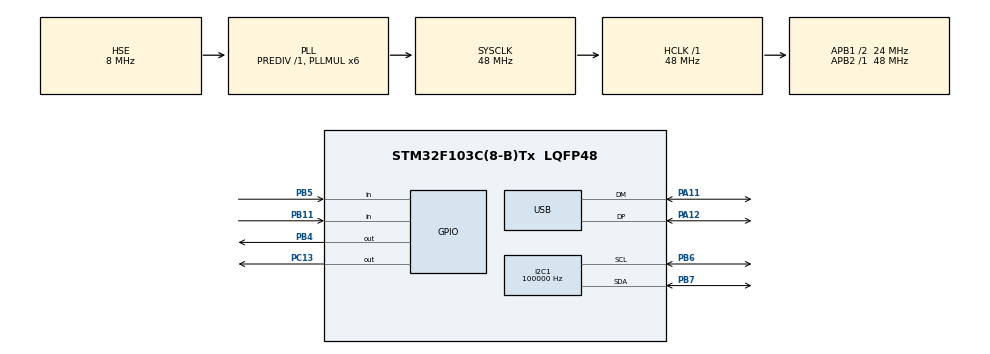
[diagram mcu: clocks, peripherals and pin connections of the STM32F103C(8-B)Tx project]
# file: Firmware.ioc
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I2C1.ClockSpeed=100000
Mcu.Family=STM32F1
Mcu.Name=STM32F103C(8-B)Tx
Mcu.Package=LQFP48
NVIC.PriorityGroup=NVIC_PRIORITYGROUP_4
NVIC.USB_LP_CAN1_RX0_IRQn=true\:0\:0\:false\:false\:true
PA11.Mode=Device
PA11.Signal=USB_DM
PA12.Mode=Device
PA12.Signal=USB_DP
PA13.Mode=Serial_Wire
PA13.Signal=SYS_JTMS-SWDIO
PA14.Mode=Serial_Wire
PA14.Signal=SYS_JTCK-SWCLK
PB11.GPIO_PuPd=GPIO_PULLUP
PB11.Signal=GPIO_Input
PB4.Signal=GPIO_Output
PB5.Signal=GPIO_Input
PB6.Mode=I2C
PB6.Signal=I2C1_SCL
PB7.Mode=I2C
PB7.Signal=I2C1_SDA
PC13-TAMPER-RTC.Signal=GPIO_Output
PD0-OSC_IN.Mode=HSE-External-Oscillator
PD0-OSC_IN.Signal=RCC_OSC_IN
PD1-OSC_OUT.Mode=HSE-External-Oscillator
PD1-OSC_OUT.Signal=RCC_OSC_OUT
ProjectManager.HeapSize=0x200
ProjectManager.StackSize=0x400
ProjectManager.TargetToolchain=MDK-ARM V5
RCC.AHBFreq_Value=48000000
RCC.APB1CLKDivider=RCC_HCLK_DIV2
RCC.APB1Freq_Value=24000000
RCC.APB1TimFreq_Value=48000000
RCC.APB2Freq_Value=48000000
RCC.APB2TimFreq_Value=48000000
RCC.HCLKFreq_Value=48000000
RCC.HSIState=RCC_HSI_ON
RCC.PLLMUL=RCC_PLL_MUL6
RCC.SYSCLKFreq_VALUE=48000000
RCC.SYSCLKSource=RCC_SYSCLKSOURCE_PLLCLK
RCC.USBFreq_Value=48000000
USB.ep0_mps=DEP0CTL_MPS_64
USB_DEVICE.CLASS_NAME_FS=CUSTOMHID
USB_DEVICE.MANUFACTURER_STRING-CUSTOM_HID_FS=A_D Electronics
USB_DEVICE.PRODUCT_STRING_CUSTOMHID_FS=Custom Touchscreen
USB_DEVICE.USBD_CUSTOMHID_OUTREPORT_BUF_SIZE-CUSTOM_HID_FS=64
USB_DEVICE.USBD_CUSTOM_HID_REPORT_DESC_SIZE-CUSTOM_HID_FS=124
USB_DEVICE.VirtualModeFS=Custom_Hid_FS
VP_USB_DEVICE_VS_USB_DEVICE_CUSTOM_HID_FS.Mode=CUSTOM_HID_FS
board=Firmware

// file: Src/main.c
#include "main.h"
#include "stm32f1xx_hal.h"
#include "usb_device.h"

/* USER CODE BEGIN Includes */
#include "GT811.h"

/* USER CODE END Includes */

I2C_HandleTypeDef hi2c1;

/* USER CODE BEGIN PV */
/* Private variables ---------------------------------------------------------*/

/* USER CODE END PV */

void SystemClock_Config(void);
void Error_Handler(void);
static void MX_GPIO_Init(void);
static void MX_I2C1_Init(void);

/* USER CODE BEGIN PFP */
/* Private function prototypes -----------------------------------------------*/

/* USER CODE END PFP */

int main(void)
{

  /* MCU Configuration----------------------------------------------------------*/

  /* Reset of all peripherals, Initializes the Flash interface and the Systick. */
  HAL_Init();

  /* Configure the system clock */
  SystemClock_Config();

  /* Initialize all configured peripherals */
  MX_GPIO_Init();
  MX_USB_DEVICE_Init();
  MX_I2C1_Init();

  /* USER CODE BEGIN 2 */

	// USB HID - https://habrahabr.ru/post/208026/
	// https://k16c.eu/2016/11/02/open-firmware-for-waveshares-7-inch-touch-screen/#more-522
	// https://github.com/pysco68/waveshare-hid

	GT811_Init();
	HAL_GPIO_WritePin(GPIOC, GPIO_PIN_13, GPIO_PIN_SET); // USB On
  /* USER CODE END 2 */

  /* Infinite loop */
  for(;;)
  {

  /* USER CODE BEGIN 3 */
		GT811_Poll();
  }
  /* USER CODE END 3 */

}

/** System Clock Configuration
*/
void SystemClock_Config(void)
{

  RCC_OscInitTypeDef RCC_OscInitStruct;
  RCC_ClkInitTypeDef RCC_ClkInitStruct;
  RCC_PeriphCLKInitTypeDef PeriphClkInit;

    /**Initializes the CPU, AHB and APB busses clocks
    */
  RCC_OscInitStruct.OscillatorType = RCC_OSCILLATORTYPE_HSE;
  RCC_OscInitStruct.HSEState = RCC_HSE_ON;
  RCC_OscInitStruct.HSEPredivValue = RCC_HSE_PREDIV_DIV1;
  RCC_OscInitStruct.HSIState = RCC_HSI_ON;
  RCC_OscInitStruct.PLL.PLLState = RCC_PLL_ON;
  RCC_OscInitStruct.PLL.PLLSource = RCC_PLLSOURCE_HSE;
  RCC_OscInitStruct.PLL.PLLMUL = RCC_PLL_MUL6;
  if (HAL_RCC_OscConfig(&RCC_OscInitStruct) != HAL_OK)
  {
    Error_Handler();
  }

    /**Initializes the CPU, AHB and APB busses clocks
    */
  RCC_ClkInitStruct.ClockType = RCC_CLOCKTYPE_HCLK|RCC_CLOCKTYPE_SYSCLK
                              |RCC_CLOCKTYPE_PCLK1|RCC_CLOCKTYPE_PCLK2;
  RCC_ClkInitStruct.SYSCLKSource = RCC_SYSCLKSOURCE_PLLCLK;
  RCC_ClkInitStruct.AHBCLKDivider = RCC_SYSCLK_DIV1;
  RCC_ClkInitStruct.APB1CLKDivider = RCC_HCLK_DIV2;
  RCC_ClkInitStruct.APB2CLKDivider = RCC_HCLK_DIV1;

  if (HAL_RCC_ClockConfig(&RCC_ClkInitStruct, FLASH_LATENCY_1) != HAL_OK)
  {
    Error_Handler();
  }

  PeriphClkInit.PeriphClockSelection = RCC_PERIPHCLK_USB;
  PeriphClkInit.UsbClockSelection = RCC_USBCLKSOURCE_PLL;
  if (HAL_RCCEx_PeriphCLKConfig(&PeriphClkInit) != HAL_OK)
  {
    Error_Handler();
  }

    /**Configure the Systick interrupt time
    */
  HAL_SYSTICK_Config(HAL_RCC_GetHCLKFreq()/1000);

    /**Configure the Systick
    */
  HAL_SYSTICK_CLKSourceConfig(SYSTICK_CLKSOURCE_HCLK);

  /* SysTick_IRQn interrupt configuration */
  HAL_NVIC_SetPriority(SysTick_IRQn, 0, 0);
}

/* I2C1 init function */
static void MX_I2C1_Init(void)
{

  hi2c1.Instance = I2C1;
  hi2c1.Init.ClockSpeed = 400000;
  hi2c1.Init.DutyCycle = I2C_DUTYCYCLE_2;
  hi2c1.Init.OwnAddress1 = 0;
  hi2c1.Init.AddressingMode = I2C_ADDRESSINGMODE_7BIT;
  hi2c1.Init.DualAddressMode = I2C_DUALADDRESS_DISABLE;
  hi2c1.Init.OwnAddress2 = 0;
  hi2c1.Init.GeneralCallMode = I2C_GENERALCALL_DISABLE;
  hi2c1.Init.NoStretchMode = I2C_NOSTRETCH_DISABLE;
  if (HAL_I2C_Init(&hi2c1) != HAL_OK)
  {
    Error_Handler();
  }

}

/** Configure pins as
        * Analog
        * Input
        * Output
        * EVENT_OUT
        * EXTI
*/
static void MX_GPIO_Init(void)
{

  GPIO_InitTypeDef GPIO_InitStruct;

  /* GPIO Ports Clock Enable */
  __HAL_RCC_GPIOC_CLK_ENABLE();
  __HAL_RCC_GPIOD_CLK_ENABLE();
  __HAL_RCC_GPIOB_CLK_ENABLE();
  __HAL_RCC_GPIOA_CLK_ENABLE();

  /*Configure GPIO pin Output Level */
  HAL_GPIO_WritePin(GPIOC, GPIO_PIN_13, GPIO_PIN_RESET);

  /*Configure GPIO pin Output Level */
  HAL_GPIO_WritePin(GPIOB, GPIO_PIN_4, GPIO_PIN_RESET);

  /*Configure GPIO pin : PC13 */
  GPIO_InitStruct.Pin = GPIO_PIN_13;
  GPIO_InitStruct.Mode = GPIO_MODE_OUTPUT_PP;
  GPIO_InitStruct.Speed = GPIO_SPEED_FREQ_LOW;
  HAL_GPIO_Init(GPIOC, &GPIO_InitStruct);

  /*Configure GPIO pin : PB11 */
  GPIO_InitStruct.Pin = GPIO_PIN_11;
  GPIO_InitStruct.Mode = GPIO_MODE_INPUT;
  GPIO_InitStruct.Pull = GPIO_PULLUP;
  HAL_GPIO_Init(GPIOB, &GPIO_InitStruct);

  /*Configure GPIO pin : PB4 */
  GPIO_InitStruct.Pin = GPIO_PIN_4;
  GPIO_InitStruct.Mode = GPIO_MODE_OUTPUT_PP;
  GPIO_InitStruct.Speed = GPIO_SPEED_FREQ_LOW;
  HAL_GPIO_Init(GPIOB, &GPIO_InitStruct);

  /*Configure GPIO pin : PB5 */
  GPIO_InitStruct.Pin = GPIO_PIN_5;
  GPIO_InitStruct.Mode = GPIO_MODE_INPUT;
  GPIO_InitStruct.Pull = GPIO_NOPULL;
  HAL_GPIO_Init(GPIOB, &GPIO_InitStruct);

}

void Error_Handler(void)
{
  while(1)
  {
  }
}
